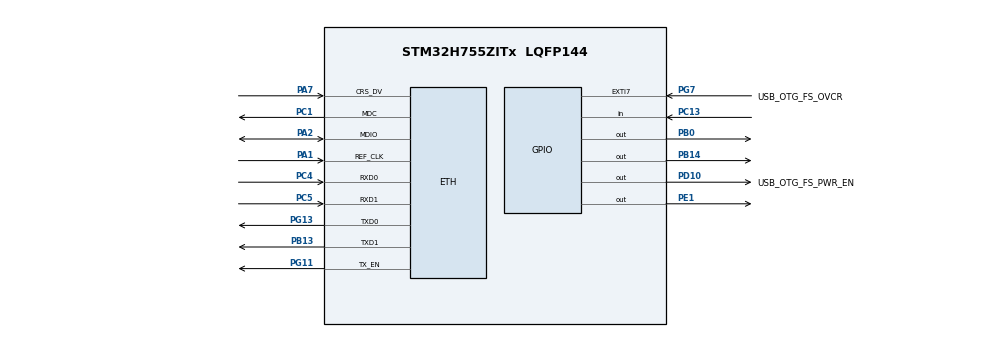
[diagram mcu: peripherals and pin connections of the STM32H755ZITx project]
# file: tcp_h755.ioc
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CORTEX_M7.AccessPermission-Cortex_Memory_Protection_Unit_Region1_Settings=MPU_REGION_FULL_ACCESS
CORTEX_M7.AccessPermission-Cortex_Memory_Protection_Unit_Region2_Settings=MPU_REGION_FULL_ACCESS
CORTEX_M7.BaseAddress-Cortex_Memory_Protection_Unit_Region1_Settings=0x30020000
CORTEX_M7.BaseAddress-Cortex_Memory_Protection_Unit_Region2_Settings=0x30040000
CORTEX_M7.CPU_DCache=Enabled
CORTEX_M7.CPU_ICache=Enabled
CORTEX_M7.DisableExec-Cortex_Memory_Protection_Unit_Region2_Settings=MPU_INSTRUCTION_ACCESS_DISABLE
CORTEX_M7.Enable-Cortex_Memory_Protection_Unit_Region0_Settings=__NULL
CORTEX_M7.Enable-Cortex_Memory_Protection_Unit_Region1_Settings=MPU_REGION_ENABLE
CORTEX_M7.Enable-Cortex_Memory_Protection_Unit_Region2_Settings=MPU_REGION_ENABLE
CORTEX_M7.IsBufferable-Cortex_Memory_Protection_Unit_Region2_Settings=MPU_ACCESS_BUFFERABLE
CORTEX_M7.IsShareable-Cortex_Memory_Protection_Unit_Region2_Settings=MPU_ACCESS_SHAREABLE
CORTEX_M7.MPU_Control=MPU_PRIVILEGED_DEFAULT
CORTEX_M7.Size-Cortex_Memory_Protection_Unit_Region1_Settings=MPU_REGION_SIZE_128KB
CORTEX_M7.Size-Cortex_Memory_Protection_Unit_Region2_Settings=MPU_REGION_SIZE_512B
CORTEX_M7.TypeExtField-Cortex_Memory_Protection_Unit_Region1_Settings=MPU_TEX_LEVEL1
CortexM4.IPs=FATFS_M4\:I,FREERTOS_M4\:I,IWDG2\:I,RCC,WWDG2\:I,DMA,BDMA,MDMA,NVIC2\:I,ETH,USART3,DEBUG,PDM2PCM_M4\:I,PWR,RESMGR_UTILITY,SYS_M4\:I,USB_DEVICE_M4\:I,USB_HOST_M4\:I,CORTEX_M4\:I,GPIO,OPENAMP_M4\:I,VREFBUF,NUCLEO-H755ZI-Q
CortexM7.IPs=FATFS_M7\:I,FREERTOS_M7\:I,IWDG1\:I,RCC\:I,WWDG1\:I,DMA\:I,BDMA\:I,MDMA\:I,NVIC1\:I,ETH\:I,USART3\:I,USB_OTG_FS\:I,SYS\:I,CORTEX_M7\:I,DEBUG\:I,PDM2PCM_M7\:I,PWR\:I,RESMGR_UTILITY\:I,USB_DEVICE_M7\:I,USB_HOST_M7\:I,GPIO\:I,OPENAMP_M7\:I,VREFBUF\:I,NUCLEO-H755ZI-Q\:I,MEMORYMAP\:I,TIM6\:I,LWIP\:I
ETH.MediaInterface=HAL_ETH_RMII_MODE
FREERTOS_M7.Tasks01=defaultTask,24,256,StartDefaultTask,Default,NULL,Dynamic,NULL,NULL
LWIP.BSP.number=1
LWIP.LWIP_BROADCAST_PING=1
LWIP.LWIP_DHCP=1
LWIP.LWIP_MULTICAST_PING=1
LWIP.MEM_SIZE=131048
LWIP.Version=v2.1.2_Cube
LWIP0.BSP.STBoard=false
LWIP0.BSP.api=BSP_COMPONENT_DRIVER
LWIP0.BSP.component=LAN8742
LWIP0.BSP.instance=LAN8742
LWIP0.BSP.name=Driver_PHY
LWIP0.BSP.semaphore=S_LAN8742
LWIP0.BSP.solution=LAN8742
Mcu.Family=STM32H7
Mcu.Name=STM32H755ZITx
Mcu.Package=LQFP144
NUCLEO-H755ZI-Q.BUTTON=1
NUCLEO-H755ZI-Q.LD1=true
NUCLEO-H755ZI-Q.LD2=true
NUCLEO-H755ZI-Q.LD3=true
NUCLEO-H755ZI-Q.VCP=true
NVIC1.ETH_IRQn=true\:5\:0\:false\:false\:true\:true\:true\:true\:true
NVIC1.EXTI15_10_IRQn=true\:5\:0\:false\:false\:true\:true\:false\:true\:true
NVIC1.PriorityGroup=NVIC_PRIORITYGROUP_4
NVIC1.TIM6_DAC_IRQn=true\:15\:0\:false\:false\:true\:false\:false\:true\:true
NVIC1.TimeBase=TIM6_DAC_IRQn
NVIC1.TimeBaseIP=TIM6
NVIC2.PriorityGroup=NVIC_PRIORITYGROUP_4
PA1.Mode=RMII
PA1.PinAttribute=CortexM7
PA1.Signal=ETH_REF_CLK
PA11.PinAttribute=CortexM7
PA11.Signal=USB_OTG_FS_DM
PA12.PinAttribute=CortexM7
PA12.Signal=USB_OTG_FS_DP
PA2.Mode=RMII
PA2.PinAttribute=CortexM7
PA2.Signal=ETH_MDIO
PA7.Mode=RMII
PA7.PinAttribute=CortexM7
PA7.Signal=ETH_CRS_DV
PA8.PinAttribute=CortexM7
PA8.Signal=USB_OTG_FS_SOF
PA9.PinAttribute=CortexM7
PA9.Signal=USB_OTG_FS_VBUS
PB0.Signal=GPIO_Output
PB13.Mode=RMII
PB13.PinAttribute=CortexM7
PB13.Signal=ETH_TXD1
PB14.Signal=GPIO_Output
PC1.Mode=RMII
PC1.PinAttribute=CortexM7
PC1.Signal=ETH_MDC
PC13.Signal=GPIO_Input
PC14-OSC32_IN\ (OSC32_IN).PinAttribute=Free
PC14-OSC32_IN\ (OSC32_IN).Signal=RCC_OSC32_IN
PC15-OSC32_OUT\ (OSC32_OUT).PinAttribute=Free
PC15-OSC32_OUT\ (OSC32_OUT).Signal=RCC_OSC32_OUT
PC4.Mode=RMII
PC4.PinAttribute=CortexM7
PC4.Signal=ETH_RXD0
PC5.Mode=RMII
PC5.PinAttribute=CortexM7
PC5.Signal=ETH_RXD1
PD10.GPIO_Label=USB_OTG_FS_PWR_EN
PD10.PinAttribute=Free
PD10.Signal=GPIO_Output
PD8.Signal=USART3_TX
PD9.Signal=USART3_RX
PE1.Signal=GPIO_Output
PG11.Mode=RMII
PG11.PinAttribute=CortexM7
PG11.Signal=ETH_TX_EN
PG13.Mode=RMII
PG13.PinAttribute=CortexM7
PG13.Signal=ETH_TXD0
PG7.GPIO_Label=USB_OTG_FS_OVCR
PG7.PinAttribute=Free
PG7.Signal=GPXTI7
PH0-OSC_IN\ (PH0).PinAttribute=Free
PH0-OSC_IN\ (PH0).Signal=RCC_OSC_IN
PH1-OSC_OUT\ (PH1).PinAttribute=Free
PH1-OSC_OUT\ (PH1).Signal=RCC_OSC_OUT
ProjectManager.HeapSize=M4-0x200,M7-0x200
ProjectManager.StackSize=M4-0x400,M7-0x400
ProjectManager.TargetToolchain=STM32CubeIDE
RCC.ADCFreq_Value=129000000
RCC.APB1Freq_Value=64000000
RCC.APB2Freq_Value=64000000
RCC.APB3Freq_Value=64000000
RCC.APB4Freq_Value=64000000
RCC.CortexFreq_Value=64000000
RCC.DIVM1=5
RCC.DIVN1=48
RCC.DIVQ1=5
RCC.HCLKFreq_Value=64000000
RCC.PLL2FRACN=0
RCC.PLL3FRACN=0
RCC.PLLFRACN=0
RCC.SYSCLKFreq_VALUE=64000000
RCC.SupplySource=PWR_DIRECT_SMPS_SUPPLY
RCC.USBFreq_Value=122880000
VP_FREERTOS_M7_VS_CMSIS_V2.Mode=CMSIS_V2
VP_LWIP_VS_Enabled.Mode=Enabled
VP_MEMORYMAP_VS_MEMORYMAP.Mode=CurAppReg
VP_NUCLEO-H755ZI-Q_VS_BSP_COMMON.Mode=COMMON
VP_SYS_M4_VS_Systick.Mode=SysTick
VP_SYS_VS_tim6.Mode=TIM6
board=NUCLEO-H755ZI-Q

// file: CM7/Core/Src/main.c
/* USER CODE BEGIN Header */
/**
  ******************************************************************************
  * @file           : main.c
  * @brief          : Main program body
  ******************************************************************************
  * @attention
  *
  * Copyright (c) 2025 STMicroelectronics.
  * All rights reserved.
  *
  * This software is licensed under terms that can be found in the LICENSE file
  * in the root directory of this software component.
  * If no LICENSE file comes with this software, it is provided AS-IS.
  *
  ******************************************************************************
  */
/* USER CODE END Header */
#include "main.h"
#include "cmsis_os.h"
#include "lwip.h"

/* USER CODE BEGIN PD */

#ifndef HSEM_ID_0
#define HSEM_ID_0 (0U) /* HW semaphore 0*/
#endif

/* USER CODE END PD */

COM_InitTypeDef BspCOMInit;

/* Definitions for defaultTask */
osThreadId_t defaultTaskHandle;
const osThreadAttr_t defaultTask_attributes = {
  .name = "defaultTask",
  .stack_size = 256 * 4,
  .priority = (osPriority_t) osPriorityNormal,
};

void SystemClock_Config(void);
static void MPU_Config(void);
static void MX_GPIO_Init(void);
void StartDefaultTask(void *argument);

/* USER CODE BEGIN 0 */
extern struct netif gnetif;

/* USER CODE END 0 */

int main(void)
{

  /* USER CODE BEGIN 1 */

#undef LWIP_PROVIDE_ERRNO
#define LWIP_ERRNO_STDINCLUDE

  /* USER CODE END 1 */
/* USER CODE BEGIN Boot_Mode_Sequence_0 */
  int32_t timeout;
/* USER CODE END Boot_Mode_Sequence_0 */

  /* MPU Configuration--------------------------------------------------------*/
  MPU_Config();

  /* Enable the CPU Cache */

  /* Enable I-Cache---------------------------------------------------------*/
  SCB_EnableICache();

  /* Enable D-Cache---------------------------------------------------------*/
  SCB_EnableDCache();

/* USER CODE BEGIN Boot_Mode_Sequence_1 */
  /* Wait until CPU2 boots and enters in stop mode or timeout*/
  timeout = 0xFFFF;
  while((__HAL_RCC_GET_FLAG(RCC_FLAG_D2CKRDY) != RESET) && (timeout-- > 0));
  if ( timeout < 0 )
  {
  Error_Handler();
  }
/* USER CODE END Boot_Mode_Sequence_1 */
  /* MCU Configuration--------------------------------------------------------*/

  /* Reset of all peripherals, Initializes the Flash interface and the Systick. */
  HAL_Init();

  /* Configure the system clock */
  SystemClock_Config();
/* USER CODE BEGIN Boot_Mode_Sequence_2 */
/* When system initialization is finished, Cortex-M7 will release Cortex-M4 by means of
HSEM notification */
/*HW semaphore Clock enable*/
__HAL_RCC_HSEM_CLK_ENABLE();
/*Take HSEM */
HAL_HSEM_FastTake(HSEM_ID_0);
/*Release HSEM in order to notify the CPU2(CM4)*/
HAL_HSEM_Release(HSEM_ID_0,0);
/* wait until CPU2 wakes up from stop mode */
timeout = 0xFFFF;
while((__HAL_RCC_GET_FLAG(RCC_FLAG_D2CKRDY) == RESET) && (timeout-- > 0));
if ( timeout < 0 )
{
Error_Handler();
}
/* USER CODE END Boot_Mode_Sequence_2 */

  /* Initialize all configured peripherals */
  MX_GPIO_Init();

  /* Init scheduler */
  osKernelInitialize();

  /* Create the thread(s) */
  /* creation of defaultTask */
  defaultTaskHandle = osThreadNew(StartDefaultTask, NULL, &defaultTask_attributes);

  /* Initialize leds */
  BSP_LED_Init(LED_GREEN);
  BSP_LED_Init(LED_YELLOW);
  BSP_LED_Init(LED_RED);

  /* Initialize USER push-button, will be used to trigger an interrupt each time it's pressed.*/
  BSP_PB_Init(BUTTON_USER, BUTTON_MODE_EXTI);

  /* Initialize COM1 port (115200, 8 bits (7-bit data + 1 stop bit), no parity */
  BspCOMInit.BaudRate   = 115200;
  BspCOMInit.WordLength = COM_WORDLENGTH_8B;
  BspCOMInit.StopBits   = COM_STOPBITS_1;
  BspCOMInit.Parity     = COM_PARITY_NONE;
  BspCOMInit.HwFlowCtl  = COM_HWCONTROL_NONE;
  if (BSP_COM_Init(COM1, &BspCOMInit) != BSP_ERROR_NONE)
  {
    Error_Handler();
  }

  /* Start scheduler */
  osKernelStart();

  /* We should never get here as control is now taken by the scheduler */

  /* Infinite loop */
  /* USER CODE BEGIN WHILE */
//  SCB_CleanInvalidateDCache();
  while (1)
  {

    /* USER CODE END WHILE */

    /* USER CODE BEGIN 3 */

// ethernetif_input(&gnetif);
// sys_check_timeouts();

  }
  /* USER CODE END 3 */
}

void SystemClock_Config(void)
{
  RCC_OscInitTypeDef RCC_OscInitStruct = {0};
  RCC_ClkInitTypeDef RCC_ClkInitStruct = {0};

  /** Supply configuration update enable
  */
  HAL_PWREx_ConfigSupply(PWR_DIRECT_SMPS_SUPPLY);

  /** Configure the main internal regulator output voltage
  */
  __HAL_PWR_VOLTAGESCALING_CONFIG(PWR_REGULATOR_VOLTAGE_SCALE3);

  while(!__HAL_PWR_GET_FLAG(PWR_FLAG_VOSRDY)) {}

  /** Initializes the RCC Oscillators according to the specified parameters
  * in the RCC_OscInitTypeDef structure.
  */
  RCC_OscInitStruct.OscillatorType = RCC_OSCILLATORTYPE_HSI;
  RCC_OscInitStruct.HSIState = RCC_HSI_DIV1;
  RCC_OscInitStruct.HSICalibrationValue = RCC_HSICALIBRATION_DEFAULT;
  RCC_OscInitStruct.PLL.PLLState = RCC_PLL_NONE;
  if (HAL_RCC_OscConfig(&RCC_OscInitStruct) != HAL_OK)
  {
    Error_Handler();
  }

  /** Initializes the CPU, AHB and APB buses clocks
  */
  RCC_ClkInitStruct.ClockType = RCC_CLOCKTYPE_HCLK|RCC_CLOCKTYPE_SYSCLK
                              |RCC_CLOCKTYPE_PCLK1|RCC_CLOCKTYPE_PCLK2
                              |RCC_CLOCKTYPE_D3PCLK1|RCC_CLOCKTYPE_D1PCLK1;
  RCC_ClkInitStruct.SYSCLKSource = RCC_SYSCLKSOURCE_HSI;
  RCC_ClkInitStruct.SYSCLKDivider = RCC_SYSCLK_DIV1;
  RCC_ClkInitStruct.AHBCLKDivider = RCC_HCLK_DIV1;
  RCC_ClkInitStruct.APB3CLKDivider = RCC_APB3_DIV1;
  RCC_ClkInitStruct.APB1CLKDivider = RCC_APB1_DIV1;
  RCC_ClkInitStruct.APB2CLKDivider = RCC_APB2_DIV1;
  RCC_ClkInitStruct.APB4CLKDivider = RCC_APB4_DIV1;

  if (HAL_RCC_ClockConfig(&RCC_ClkInitStruct, FLASH_LATENCY_1) != HAL_OK)
  {
    Error_Handler();
  }
}

static void MX_GPIO_Init(void)
{
  GPIO_InitTypeDef GPIO_InitStruct = {0};

  /* GPIO Ports Clock Enable */
  __HAL_RCC_GPIOC_CLK_ENABLE();
  __HAL_RCC_GPIOA_CLK_ENABLE();
  __HAL_RCC_GPIOB_CLK_ENABLE();
  __HAL_RCC_GPIOG_CLK_ENABLE();

  /*Configure GPIO pins : PA8 PA11 PA12 */
  GPIO_InitStruct.Pin = GPIO_PIN_8|GPIO_PIN_11|GPIO_PIN_12;
  GPIO_InitStruct.Mode = GPIO_MODE_AF_PP;
  GPIO_InitStruct.Pull = GPIO_NOPULL;
  GPIO_InitStruct.Speed = GPIO_SPEED_FREQ_LOW;
  GPIO_InitStruct.Alternate = GPIO_AF10_OTG1_FS;
  HAL_GPIO_Init(GPIOA, &GPIO_InitStruct);

}

void StartDefaultTask(void *argument)
{
  /* init code for LWIP */
  MX_LWIP_Init();
  /* USER CODE BEGIN 5 */
  /* Infinite loop */
  for(;;)
  {

	  SCB_CleanInvalidateDCache();
//	  ethernetif_input(&gnetif);
//	   sys_check_timeouts();
	  if (dhcp_supplied_address(&gnetif)) {
		  char ip_str[16]; // Buffer for IP address string IP address to string using ip4addr_ntoa_r

		  if (ip4addr_ntoa_r(&gnetif.ip_addr, ip_str, sizeof(ip_str)) != NULL) {
			  printf("DHCP assigned IP: %s\n", ip_str);
		  } //if ip
		  else {
			  printf("Error converting IP address\n");
		  } //else if
	  }//  main if
	  else {
		  printf("Waiting for DHCP...\n");
	  }//else main

	//  printf("IP: %s\n", ip4addr_ntoa(&gnetif.ip_addr));

    osDelay(1);
  }
  /* USER CODE END 5 */
}

 /* MPU Configuration */

void MPU_Config(void)
{
  MPU_Region_InitTypeDef MPU_InitStruct = {0};

  /* Disables the MPU */
  HAL_MPU_Disable();

  /** Initializes and configures the Region and the memory to be protected
  */
  MPU_InitStruct.Enable = MPU_REGION_ENABLE;
  MPU_InitStruct.Number = MPU_REGION_NUMBER1;
  MPU_InitStruct.BaseAddress = 0x30020000;
  MPU_InitStruct.Size = MPU_REGION_SIZE_128KB;
  MPU_InitStruct.SubRegionDisable = 0x0;
  MPU_InitStruct.TypeExtField = MPU_TEX_LEVEL1;
  MPU_InitStruct.AccessPermission = MPU_REGION_FULL_ACCESS;
  MPU_InitStruct.DisableExec = MPU_INSTRUCTION_ACCESS_ENABLE;
  MPU_InitStruct.IsShareable = MPU_ACCESS_NOT_SHAREABLE;
  MPU_InitStruct.IsCacheable = MPU_ACCESS_NOT_CACHEABLE;
  MPU_InitStruct.IsBufferable = MPU_ACCESS_NOT_BUFFERABLE;

  HAL_MPU_ConfigRegion(&MPU_InitStruct);

  /** Initializes and configures the Region and the memory to be protected
  */
  MPU_InitStruct.Number = MPU_REGION_NUMBER2;
  MPU_InitStruct.BaseAddress = 0x30040000;
  MPU_InitStruct.Size = MPU_REGION_SIZE_512B;
  MPU_InitStruct.TypeExtField = MPU_TEX_LEVEL0;
  MPU_InitStruct.DisableExec = MPU_INSTRUCTION_ACCESS_DISABLE;
  MPU_InitStruct.IsShareable = MPU_ACCESS_SHAREABLE;
  MPU_InitStruct.IsBufferable = MPU_ACCESS_BUFFERABLE;

  HAL_MPU_ConfigRegion(&MPU_InitStruct);
  /* Enables the MPU */
  HAL_MPU_Enable(MPU_PRIVILEGED_DEFAULT);

}

void HAL_TIM_PeriodElapsedCallback(TIM_HandleTypeDef *htim)
{
  if (htim->Instance == TIM6) {
    HAL_IncTick();
  }
}

void Error_Handler(void)
{
  __disable_irq();
  while (1)
  {
  }
}
